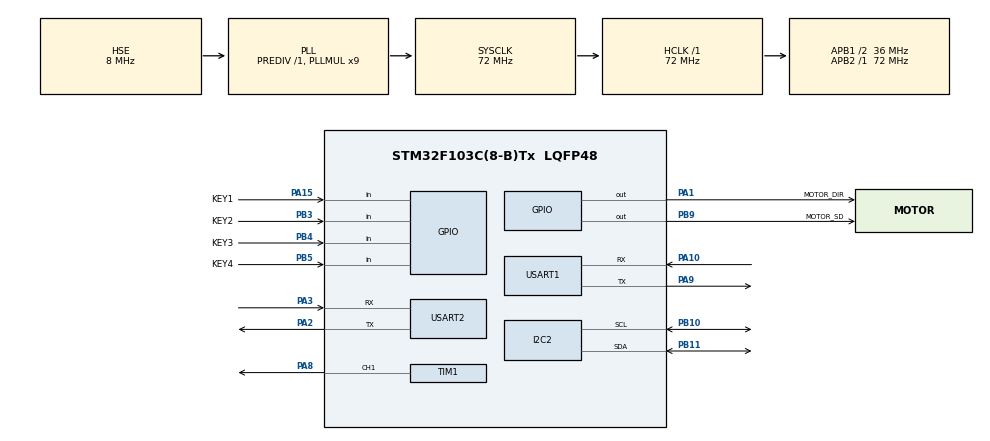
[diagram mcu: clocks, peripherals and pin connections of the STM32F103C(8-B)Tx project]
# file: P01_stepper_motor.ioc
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FREERTOS.Mutexes01=i2cMutex,Dynamic,NULL,Available
FREERTOS.Tasks01=Key_Task,24,128,StartKeyTask,As weak,NULL,Dynamic,NULL,NULL;Display_Task,16,128,StartDisplayTask,As weak,NULL,Dynamic,NULL,NULL;Modbus_Task,32,256,StartModbusTask,As weak,NULL,Dynamic,NULL,NULL
FREERTOS.configTOTAL_HEAP_SIZE=6144
Mcu.Family=STM32F1
Mcu.Name=STM32F103C(8-B)Tx
Mcu.Package=LQFP48
NVIC.PriorityGroup=NVIC_PRIORITYGROUP_4
NVIC.TIM1_CC_IRQn=true\:5\:0\:true\:false\:true\:true\:true\:true\:true
NVIC.TIM3_IRQn=true\:5\:0\:false\:false\:false\:true\:true\:true\:true
NVIC.TIM4_IRQn=true\:15\:0\:false\:false\:true\:false\:false\:true\:true
NVIC.TimeBase=TIM4_IRQn
NVIC.TimeBaseIP=TIM4
NVIC.USART2_IRQn=true\:5\:0\:false\:false\:false\:true\:true\:true\:true
PA1.GPIO_Label=MOTOR_DIR
PA1.Signal=GPIO_Output
PA10.Mode=Asynchronous
PA10.Signal=USART1_RX
PA13.Mode=Serial_Wire
PA13.Signal=SYS_JTMS-SWDIO
PA14.Mode=Serial_Wire
PA14.Signal=SYS_JTCK-SWCLK
PA15.GPIO_Label=KEY1
PA15.GPIO_PuPd=GPIO_PULLUP
PA15.Signal=GPIO_Input
PA2.Mode=Asynchronous
PA2.Signal=USART2_TX
PA3.Mode=Asynchronous
PA3.Signal=USART2_RX
PA8.Signal=S_TIM1_CH1
PA9.Mode=Asynchronous
PA9.Signal=USART1_TX
PB10.Mode=I2C
PB10.Signal=I2C2_SCL
PB11.Mode=I2C
PB11.Signal=I2C2_SDA
PB3.GPIO_Label=KEY2
PB3.GPIO_PuPd=GPIO_PULLUP
PB3.Signal=GPIO_Input
PB4.GPIO_Label=KEY3
PB4.GPIO_PuPd=GPIO_PULLUP
PB4.Signal=GPIO_Input
PB5.GPIO_Label=KEY4
PB5.GPIO_PuPd=GPIO_PULLUP
PB5.Signal=GPIO_Input
PB9.GPIO_Label=MOTOR_SD
PB9.GPIO_Speed=GPIO_SPEED_FREQ_HIGH
PB9.PinState=GPIO_PIN_RESET
PB9.Signal=GPIO_Output
PC14-OSC32_IN.Mode=LSE-External-Oscillator
PC14-OSC32_IN.Signal=RCC_OSC32_IN
PC15-OSC32_OUT.Mode=LSE-External-Oscillator
PC15-OSC32_OUT.Signal=RCC_OSC32_OUT
PD0-OSC_IN.Mode=HSE-External-Oscillator
PD0-OSC_IN.Signal=RCC_OSC_IN
PD1-OSC_OUT.Mode=HSE-External-Oscillator
PD1-OSC_OUT.Signal=RCC_OSC_OUT
ProjectManager.HeapSize=0x200
ProjectManager.StackSize=0x400
ProjectManager.TargetToolchain=MDK-ARM V5.32
RCC.AHBFreq_Value=72000000
RCC.APB1CLKDivider=RCC_HCLK_DIV2
RCC.APB1Freq_Value=36000000
RCC.APB1TimFreq_Value=72000000
RCC.APB2Freq_Value=72000000
RCC.APB2TimFreq_Value=72000000
RCC.HCLKFreq_Value=72000000
RCC.PLLMUL=RCC_PLL_MUL9
RCC.PLLSourceVirtual=RCC_PLLSOURCE_HSE
RCC.SYSCLKFreq_VALUE=72000000
RCC.SYSCLKSource=RCC_SYSCLKSOURCE_PLLCLK
RCC.USBFreq_Value=72000000
SH.S_TIM1_CH1.0=TIM1_CH1,Output Compare1 CH1
TIM1.Channel-Output\ Compare1\ CH1=TIM_CHANNEL_1
TIM1.OCMode_1=TIM_OCMODE_TOGGLE
TIM1.Prescaler=72 -1
TIM3.Period=35-1
TIM3.Prescaler=3600-1
USART1.VirtualMode=VM_ASYNC
USART2.VirtualMode=VM_ASYNC
VP_FREERTOS_VS_CMSIS_V2.Mode=CMSIS_V2
VP_SYS_VS_tim4.Mode=TIM4
VP_TIM1_VS_ClockSourceINT.Mode=Internal
VP_TIM3_VS_ClockSourceINT.Mode=Internal
board=custom

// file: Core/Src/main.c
/* USER CODE BEGIN Header */
/**
  ******************************************************************************
  * @file           : main.c
  * @brief          : Main program body
  ******************************************************************************
  * @attention
  *
  * Copyright (c) 2026 STMicroelectronics.
  * All rights reserved.
  *
  * This software is licensed under terms that can be found in the LICENSE file
  * in the root directory of this software component.
  * If no LICENSE file comes with this software, it is provided AS-IS.
  *
  ******************************************************************************
  */
/* USER CODE END Header */
#include "main.h"
#include "cmsis_os.h"
#include "i2c.h"
#include "tim.h"
#include "usart.h"
#include "gpio.h"

void SystemClock_Config(void);
void MX_FREERTOS_Init(void);

int main(void)
{

  /* MCU Configuration--------------------------------------------------------*/

  /* Reset of all peripherals, Initializes the Flash interface and the Systick. */
  HAL_Init();

  /* Configure the system clock */
  SystemClock_Config();

  /* Initialize all configured peripherals */
  MX_GPIO_Init();
  MX_I2C2_Init();
  MX_USART1_UART_Init();
  MX_TIM1_Init();
  MX_TIM3_Init();
  MX_USART2_UART_Init();

  /* Init scheduler */
  osKernelInitialize();  /* Call init function for freertos objects (in cmsis_os2.c) */
  MX_FREERTOS_Init();

  /* Start scheduler */
  osKernelStart();

  /* We should never get here as control is now taken by the scheduler */

  /* Infinite loop */
  while (1)
  {

  }
}

void SystemClock_Config(void)
{
  RCC_OscInitTypeDef RCC_OscInitStruct = {0};
  RCC_ClkInitTypeDef RCC_ClkInitStruct = {0};

  /** Initializes the RCC Oscillators according to the specified parameters
  * in the RCC_OscInitTypeDef structure.
  */
  RCC_OscInitStruct.OscillatorType = RCC_OSCILLATORTYPE_HSE;
  RCC_OscInitStruct.HSEState = RCC_HSE_ON;
  RCC_OscInitStruct.HSEPredivValue = RCC_HSE_PREDIV_DIV1;
  RCC_OscInitStruct.HSIState = RCC_HSI_ON;
  RCC_OscInitStruct.PLL.PLLState = RCC_PLL_ON;
  RCC_OscInitStruct.PLL.PLLSource = RCC_PLLSOURCE_HSE;
  RCC_OscInitStruct.PLL.PLLMUL = RCC_PLL_MUL9;
  if (HAL_RCC_OscConfig(&RCC_OscInitStruct) != HAL_OK)
  {
    Error_Handler();
  }

  /** Initializes the CPU, AHB and APB buses clocks
  */
  RCC_ClkInitStruct.ClockType = RCC_CLOCKTYPE_HCLK|RCC_CLOCKTYPE_SYSCLK
                              |RCC_CLOCKTYPE_PCLK1|RCC_CLOCKTYPE_PCLK2;
  RCC_ClkInitStruct.SYSCLKSource = RCC_SYSCLKSOURCE_PLLCLK;
  RCC_ClkInitStruct.AHBCLKDivider = RCC_SYSCLK_DIV1;
  RCC_ClkInitStruct.APB1CLKDivider = RCC_HCLK_DIV2;
  RCC_ClkInitStruct.APB2CLKDivider = RCC_HCLK_DIV1;

  if (HAL_RCC_ClockConfig(&RCC_ClkInitStruct, FLASH_LATENCY_2) != HAL_OK)
  {
    Error_Handler();
  }
}

void HAL_TIM_PeriodElapsedCallback(TIM_HandleTypeDef *htim)
{
  if (htim->Instance == TIM4)
  {
    HAL_IncTick();
  }
}

void Error_Handler(void)
{
  __disable_irq();
  while (1)
  {
  }
}

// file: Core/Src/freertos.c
/* USER CODE BEGIN Header */
/**
  ******************************************************************************
  * File Name          : freertos.c
  * Description        : Code for freertos applications
  ******************************************************************************
  * @attention
  *
  * Copyright (c) 2026 STMicroelectronics.
  * All rights reserved.
  *
  * This software is licensed under terms that can be found in the LICENSE file
  * in the root directory of this software component.
  * If no LICENSE file comes with this software, it is provided AS-IS.
  *
  ******************************************************************************
  */
/* USER CODE END Header */

#include "FreeRTOS.h"
#include "task.h"
#include "main.h"
#include "cmsis_os.h"

/* USER CODE BEGIN Variables */
osMutexId_t I2C_Mutex; // OLED 与 EEPROM 共用 I2C2 的互斥锁

/* USER CODE END Variables */
/* Definitions for Key_Task */
osThreadId_t Key_TaskHandle;
const osThreadAttr_t Key_Task_attributes = {
  .name = "Key_Task",
  .stack_size = 128 * 4,
  .priority = (osPriority_t) osPriorityNormal,
};
/* Definitions for Display_Task */
osThreadId_t Display_TaskHandle;
const osThreadAttr_t Display_Task_attributes = {
  .name = "Display_Task",
  .stack_size = 128 * 4,
  .priority = (osPriority_t) osPriorityBelowNormal,
};
/* Definitions for Modbus_Task */
osThreadId_t Modbus_TaskHandle;
const osThreadAttr_t Modbus_Task_attributes = {
  .name = "Modbus_Task",
  .stack_size = 256 * 4,
  .priority = (osPriority_t) osPriorityAboveNormal,
};
/* Definitions for i2cMutex */
osMutexId_t i2cMutexHandle;
const osMutexAttr_t i2cMutex_attributes = {
  .name = "i2cMutex"
};

void StartKeyTask(void *argument);
void StartDisplayTask(void *argument);
void StartModbusTask(void *argument);

void MX_FREERTOS_Init(void); /* (MISRA C 2004 rule 8.1) */

void MX_FREERTOS_Init(void) {
  /* Create the mutex(es) */
  /* creation of i2cMutex */
  i2cMutexHandle = osMutexNew(&i2cMutex_attributes);

  /* USER CODE BEGIN RTOS_MUTEX */
  /* add mutexes, ... */
  I2C_Mutex = osMutexNew(NULL); // 创建 I2C2 总线互斥锁
  /* USER CODE END RTOS_MUTEX */

  /* Create the thread(s) */
  /* creation of Key_Task */
  Key_TaskHandle = osThreadNew(StartKeyTask, NULL, &Key_Task_attributes);

  /* creation of Display_Task */
  Display_TaskHandle = osThreadNew(StartDisplayTask, NULL, &Display_Task_attributes);

  /* creation of Modbus_Task */
  Modbus_TaskHandle = osThreadNew(StartModbusTask, NULL, &Modbus_Task_attributes);

}

__weak void StartKeyTask(void *argument)
{
  for(;;)
  {
    osDelay(1);
  }
}

__weak void StartDisplayTask(void *argument)
{
  for(;;)
  {
    osDelay(1);
  }
}

__weak void StartModbusTask(void *argument)
{
  for(;;)
  {
    osDelay(1);
  }
}
